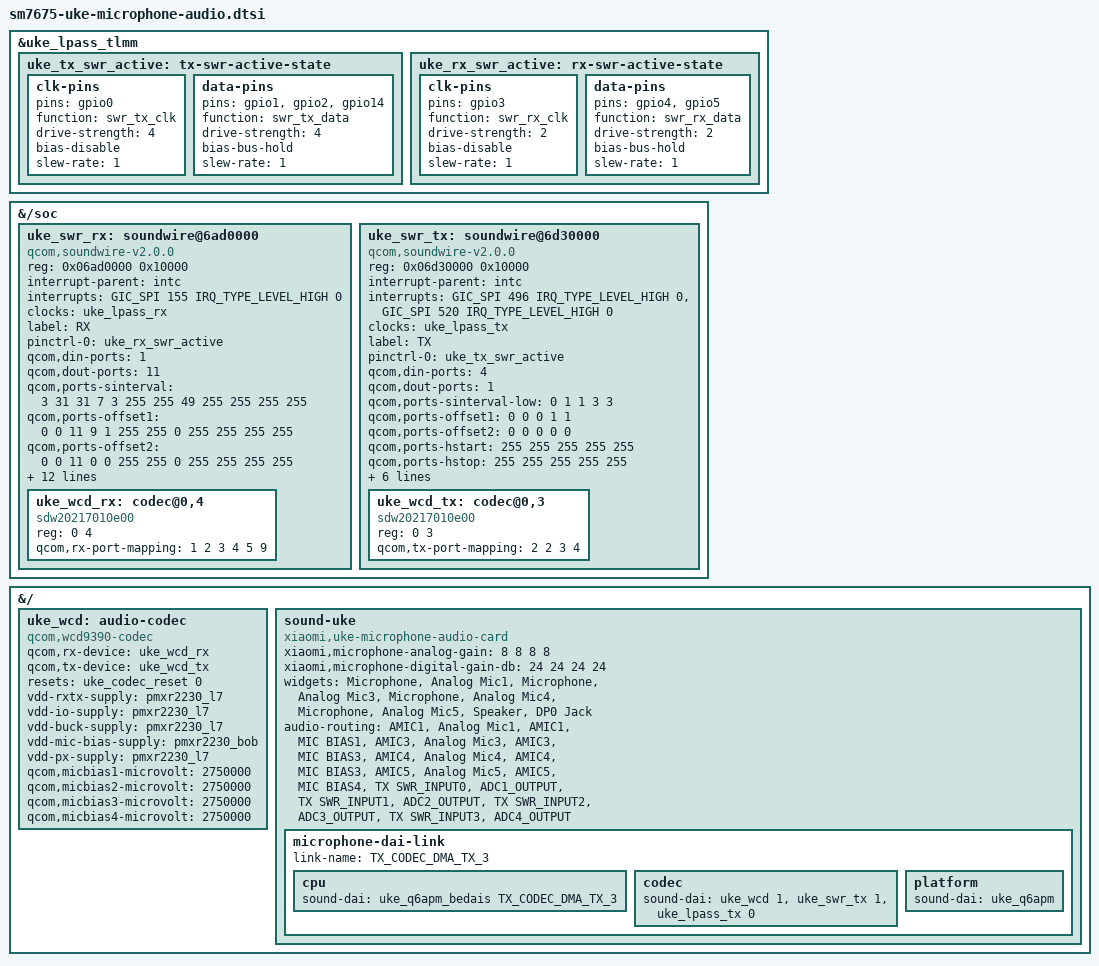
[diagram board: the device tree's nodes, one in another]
/* SPDX-License-Identifier: GPL-2.0-only OR BSD-2-Clause */
/*
 * Individual onboard AMIC capture, included after the existing speaker profile.
 * Uke live OEM DT: L7B 1.8 V, BOB 3.296 V, MICBIAS 2.75 V, LPI pins/IRQs.
 * SoundWire v2 transport/port ABI: upstream SM8650 at 4056b3c9.
 * Four-channel order: ADC1/3/4/2 on SWR_INPUT0/2/3/1 and DEC0..3.
 * Physical position and electrical behavior require separate qualification.
 */
#include <dt-bindings/interrupt-controller/arm-gic.h>

&uke_lpass_tlmm {
	uke_tx_swr_active: tx-swr-active-state {
		clk-pins {
			pins = "gpio0";
			function = "swr_tx_clk";
			drive-strength = <4>;
			bias-disable;
			slew-rate = <1>;
		};
		data-pins {
			pins = "gpio1", "gpio2", "gpio14";
			function = "swr_tx_data";
			drive-strength = <4>;
			bias-bus-hold;
			slew-rate = <1>;
		};
	};

	uke_rx_swr_active: rx-swr-active-state {
		clk-pins {
			pins = "gpio3";
			function = "swr_rx_clk";
			drive-strength = <2>;
			bias-disable;
			slew-rate = <1>;
		};
		data-pins {
			pins = "gpio4", "gpio5";
			function = "swr_rx_data";
			drive-strength = <2>;
			bias-bus-hold;
			slew-rate = <1>;
		};
	};
};

&{/soc} {
	uke_swr_rx: soundwire@6ad0000 {
		compatible = "qcom,soundwire-v2.0.0";
		reg = <0x06ad0000 0x10000>;
		interrupt-parent = <&intc>;
		interrupts = <GIC_SPI 155 IRQ_TYPE_LEVEL_HIGH 0>;
		clocks = <&uke_lpass_rx>;
		clock-names = "iface";
		label = "RX";
		pinctrl-names = "default";
		pinctrl-0 = <&uke_rx_swr_active>;
		qcom,din-ports = <1>;
		qcom,dout-ports = <11>;
		qcom,ports-sinterval = /bits/ 16 <3 31 31 7 3 255 255 49 255 255 255 255>;
		qcom,ports-offset1 = /bits/ 8 <0 0 11 9 1 255 255 0 255 255 255 255>;
		qcom,ports-offset2 = /bits/ 8 <0 0 11 0 0 255 255 0 255 255 255 255>;
		qcom,ports-hstart = /bits/ 8 <255 3 255 255 255 255 255 0 255 255 255 255>;
		qcom,ports-hstop = /bits/ 8 <255 6 255 255 255 255 255 15 255 255 255 255>;
		qcom,ports-word-length = /bits/ 8 <1 7 4 255 255 255 255 24 255 255 255 255>;
		qcom,ports-block-pack-mode = /bits/ 8 <255 0 1 255 255 255 255 1 255 255 255 255>;
		qcom,ports-block-group-count = /bits/ 8 <255 255 255 1 3 255 255 0 255 255 255 255>;
		qcom,ports-lane-control = /bits/ 8 <1 0 0 0 0 255 255 1 255 255 255 255>;
		#address-cells = <2>;
		#size-cells = <0>;
		#sound-dai-cells = <1>;

		uke_wcd_rx: codec@0,4 {
			compatible = "sdw20217010e00";
			reg = <0 4>;
			qcom,rx-port-mapping = <1 2 3 4 5 9>;
		};
	};

	uke_swr_tx: soundwire@6d30000 {
		compatible = "qcom,soundwire-v2.0.0";
		reg = <0x06d30000 0x10000>;
		interrupt-parent = <&intc>;
		interrupts = <GIC_SPI 496 IRQ_TYPE_LEVEL_HIGH 0>,
			     <GIC_SPI 520 IRQ_TYPE_LEVEL_HIGH 0>;
		interrupt-names = "core", "wakeup";
		clocks = <&uke_lpass_tx>;
		clock-names = "iface";
		label = "TX";
		pinctrl-names = "default";
		pinctrl-0 = <&uke_tx_swr_active>;
		qcom,din-ports = <4>;
		qcom,dout-ports = <1>;
		qcom,ports-sinterval-low = /bits/ 8 <0 1 1 3 3>;
		qcom,ports-offset1 = /bits/ 8 <0 0 0 1 1>;
		qcom,ports-offset2 = /bits/ 8 <0 0 0 0 0>;
		qcom,ports-hstart = /bits/ 8 <255 255 255 255 255>;
		qcom,ports-hstop = /bits/ 8 <255 255 255 255 255>;
		qcom,ports-word-length = /bits/ 8 <255 255 255 255 255>;
		qcom,ports-block-pack-mode = /bits/ 8 <255 255 255 255 255>;
		qcom,ports-block-group-count = /bits/ 8 <255 255 255 255 255>;
		qcom,ports-lane-control = /bits/ 8 <255 1 2 0 0>;
		#address-cells = <2>;
		#size-cells = <0>;
		#sound-dai-cells = <1>;

		uke_wcd_tx: codec@0,3 {
			compatible = "sdw20217010e00";
			reg = <0 3>;
			qcom,tx-port-mapping = <2 2 3 4>;
		};
	};
};

&{/} {
	uke_wcd: audio-codec {
		compatible = "qcom,wcd9390-codec";
		#sound-dai-cells = <1>;
		qcom,rx-device = <&uke_wcd_rx>;
		qcom,tx-device = <&uke_wcd_tx>;
		resets = <&uke_codec_reset 0>;
		vdd-rxtx-supply = <&pmxr2230_l7>;
		vdd-io-supply = <&pmxr2230_l7>;
		vdd-buck-supply = <&pmxr2230_l7>;
		vdd-mic-bias-supply = <&pmxr2230_bob>;
		vdd-px-supply = <&pmxr2230_l7>;
		qcom,micbias1-microvolt = <2750000>;
		qcom,micbias2-microvolt = <2750000>;
		qcom,micbias3-microvolt = <2750000>;
		qcom,micbias4-microvolt = <2750000>;
	};

	sound-uke {
		compatible = "xiaomi,uke-microphone-audio-card";
		/* ADC1..4 control indices; DEC0..3 digital gain in dB. */
		xiaomi,microphone-analog-gain = <8 8 8 8>;
		xiaomi,microphone-digital-gain-db = <24 24 24 24>;
		widgets = "Microphone", "Analog Mic1",
			  "Microphone", "Analog Mic3",
			  "Microphone", "Analog Mic4",
			  "Microphone", "Analog Mic5", "Speaker", "DP0 Jack";
		audio-routing = "AMIC1", "Analog Mic1",
				"AMIC1", "MIC BIAS1",
				"AMIC3", "Analog Mic3",
				"AMIC3", "MIC BIAS3",
				"AMIC4", "Analog Mic4",
				"AMIC4", "MIC BIAS3",
				"AMIC5", "Analog Mic5",
				"AMIC5", "MIC BIAS4",
				"TX SWR_INPUT0", "ADC1_OUTPUT",
				"TX SWR_INPUT1", "ADC2_OUTPUT",
				"TX SWR_INPUT2", "ADC3_OUTPUT",
				"TX SWR_INPUT3", "ADC4_OUTPUT";

		microphone-dai-link {
			link-name = "TX_CODEC_DMA_TX_3";
			cpu { sound-dai = <&uke_q6apm_bedais TX_CODEC_DMA_TX_3>; };
			codec {
				/* DAI 0 is playback; the first capture DAI follows one dout. */
				sound-dai = <&uke_wcd 1>, <&uke_swr_tx 1>, <&uke_lpass_tx 0>;
			};
			platform { sound-dai = <&uke_q6apm>; };
		};
	};
};
